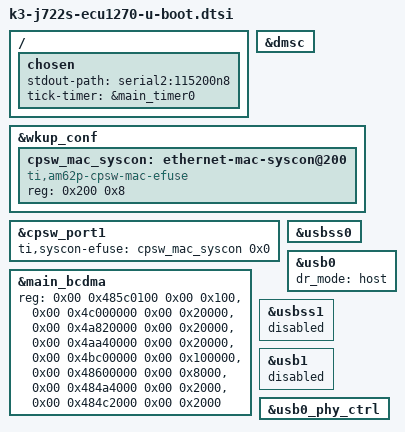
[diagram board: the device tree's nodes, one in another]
// SPDX-License-Identifier: GPL-2.0
/*
 * Common J722S ECU1270 dts file for SPLs
 * Copyright (C) 2024 Texas Instruments Incorporated - https://www.ti.com/
 */

#include "k3-j722s-ecu1270-binman.dtsi"

/ {
	chosen {
		stdout-path = "serial2:115200n8";
		tick-timer = &main_timer0;
	};
};

&dmsc {
	bootph-pre-ram;
};

&wkup_conf {
	cpsw_mac_syscon: ethernet-mac-syscon@200 {
		compatible = "ti,am62p-cpsw-mac-efuse", "syscon";
		reg = <0x200 0x8>;
	};
};

&cpsw_port1 {
	ti,syscon-efuse = <&cpsw_mac_syscon 0x0>;
};

&main_bcdma {
	bootph-pre-ram;
	reg = <0x00 0x485c0100 0x00 0x100>,
	      <0x00 0x4c000000 0x00 0x20000>,
	      <0x00 0x4a820000 0x00 0x20000>,
	      <0x00 0x4aa40000 0x00 0x20000>,
	      <0x00 0x4bc00000 0x00 0x100000>,
	      <0x00 0x48600000 0x00 0x8000>,
	      <0x00 0x484a4000 0x00 0x2000>,
	      <0x00 0x484c2000 0x00 0x2000>;
	reg-names = "gcfg", "bchanrt", "rchanrt", "tchanrt",
		    "ringrt", "cfg", "tchan", "rchan";
};

&usbss0 {
	bootph-pre-ram;
};

&usb0 {
	dr_mode = "host";
	bootph-pre-ram;
};

&usbss1 {
	status = "disabled";
};

&usb1 {
	status = "disabled";
};

&usb0_phy_ctrl {
	bootph-pre-ram;
};

